# WKUP_VTM0_CFG0 register map
Vendor: Texas Instruments
Peripheral module from a debugger description file (folder am65x).
Registers are 32-bit, read-only, reset values left out (the file's numbers can be read two ways) unless marked. A register's access mark holds for its fields unless they carry their own. Offsets are as the file gives them; lines under a group give offsets from that group; [hi:lo] are bit positions; {n}, {i} and the like mark numbered series; 'fields as' and 'values as' point back to an identical list; <NAME> marks a mode.

## WKUP_VTM0_CFG0
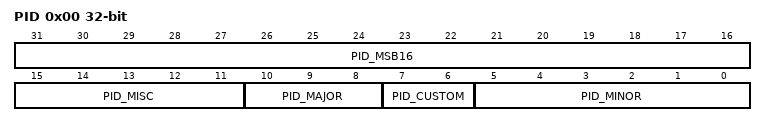
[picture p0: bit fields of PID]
0x00 PID — register
  [31:16] PID_MSB16, [15:11] PID_MISC, [10:8] PID_MAJOR, [7:6] PID_CUSTOM, [5:0] PID_MINOR
